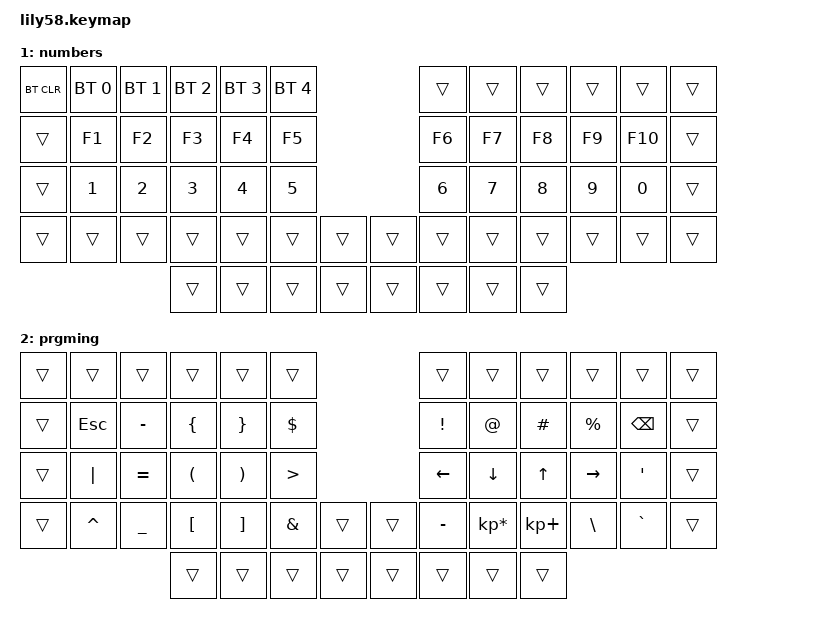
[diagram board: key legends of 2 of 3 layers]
/*
 * Copyright (c) 2020 The ZMK Contributors
 *
 * SPDX-License-Identifier: MIT
 */

#include <behaviors.dtsi>
#include <dt-bindings/zmk/bt.h>
#include <dt-bindings/zmk/keys.h>

&lt { tapping-term-ms = <200>; };

&mt { flavor = "tap-preferred"; };

/ {
    macros {
        screenshot: screenshot {
            compatible = "zmk,behavior-macro";
            #binding-cells = <0>;
            bindings = <&kp LS(LG(R))>;
            label = "SCREENSHOT";
        };

        formatcode: formatcode {
            compatible = "zmk,behavior-macro";
            #binding-cells = <0>;
            bindings = <&kp LS(LA(F))>;
            label = "FORMATCODE";
        };
    };

    keymap {
        compatible = "zmk,keymap";

        default_layer {
            // ------------------------------------------------------------------------------------------------------------
            // |       |        |        |        |        |            |                          |       |       |       |      |       |       |
            // |       |   Q    |    W   |   E    |   R    |  T         |                          |  Y    |  U    |  I    |  O   |   P   |       |
            // |       | LGUI/A | LALT/S | LCTL/D | LSFT/F |  G         |                          |  H    |  J    |  K    |  L   |   ;   |       |
            // |       |  Z     |  X     |  C     |  V     |  B         |            |     |       |  N    |  M    |  ,    |  .   |   /   |       |
            //                           |   | ENTR/LAYER3 | BKSPCE     | TAB/LAYER1 |     | SPACE | LAYER2|       |       |
            //                                   

            bindings = <
&trans  &trans      &trans      &trans       &trans         &trans                               &trans  &trans       &trans       &trans      &trans              &trans
&trans  &kp Q       &kp W       &kp E        &kp R          &kp T                                &kp Y   &kp U        &kp I        &kp O       &kp P               &trans
&trans  &mt LGUI A  &mt LALT S  &mt LCTRL D  &mt LSHFT F    &kp G                                &kp H   &mt RSHFT J  &mt RCTRL K  &mt LALT L  &mt RGUI SEMICOLON  &trans
&trans  &kp Z       &kp X       &kp C        &kp V          &kp B    &screenshot    &formatcode  &kp N   &kp M        &kp COMMA    &kp DOT     &kp FSLH            &trans
                                &trans       &kp BACKSPACE  &kp TAB  &lt 1 ENTER    &kp SPACE    &mo 2   &trans
            >;
        };

        numbers {
            // ------------------------------------------------------------------------------------------------------------
            // | BTCLR | BT1 | BT2 |  BT3 |  BT4 |  BT5 |                   |      |       |       |      |       |       |
            // |       |  F1 |  F2 |  F3  |  F4  |  F5  |                   |  F6  |  F7   |  F8   |  F9  |  F10  |       |
            // |       |  1  |  2  |  3   |  4   |  5   |                   |  6   |  7    |  8    |   9  |   0   |       |
            // |       |     |     |      |      |      |        |  |       |      |       |       |      |       |       |
            //                     |      |      |      |        |  |       |      |       |       |

            bindings = <
&bt BT_CLR  &bt BT_SEL 0  &bt BT_SEL 1  &bt BT_SEL 2  &bt BT_SEL 3  &bt BT_SEL 4                    &trans  &trans  &trans  &trans  &trans   &trans
&trans      &kp F1        &kp F2        &kp F3        &kp F4        &kp F5                          &kp F6  &kp F7  &kp F8  &kp F9  &kp F10  &trans
&trans      &kp N1        &kp N2        &kp N3        &kp N4        &kp N5                          &kp N6  &kp N7  &kp N8  &kp N9  &kp N0   &trans
&trans      &trans        &trans        &trans        &trans        &trans        &trans    &trans  &trans  &trans  &trans  &trans  &trans   &trans
                                        &trans        &trans        &trans        &trans    &trans  &trans  &trans  &trans
            >;
        };

        prgming {
            // ------------------------------------------------------------------------------------------------------------
            // |       |     |     |      |      |      |                   |      |       |       |      |       |       |
            // |  ESC  |  *  |  -  |  {   |  }   |  $   |                   |  !   |   @   |   #   |  %   | BKSPC |       |
            // | SHIFT |  |  |  =  |  (   |  )   |  >   |                   |  <-  |   v   |   ^   |  ->  |  '/"  |       |
            // | LCTRL |  ^  |  _  |  [   |  ]   |  &   |        |  |       |  -   |   *   |   +   |   \  |  ~    |       |
            //                     |      |      |      |        |  |       |      |       |       |

            bindings = <
&trans  &trans      &trans     &trans    &trans    &trans                        &trans     &trans           &trans       &trans     &trans     &trans
&trans  &kp ESCAPE  &kp MINUS  &kp LBRC  &kp RBRC  &kp DOLLAR                    &kp EXCL   &kp AT           &kp HASH     &kp PRCNT  &kp BSPC   &trans
&trans  &kp PIPE    &kp EQUAL  &kp LPAR  &kp RPAR  &kp GT                        &kp LEFT   &kp DOWN         &kp UP       &kp RIGHT  &kp SQT    &trans
&trans  &kp CARET   &kp UNDER  &kp LBKT  &kp RBKT  &kp AMPS    &trans    &trans  &kp MINUS  &kp KP_MULTIPLY  &kp KP_PLUS  &kp BSLH   &kp GRAVE  &trans
                               &trans    &trans    &trans      &trans    &trans  &trans     &trans           &trans
            >;
        };
    };
};
